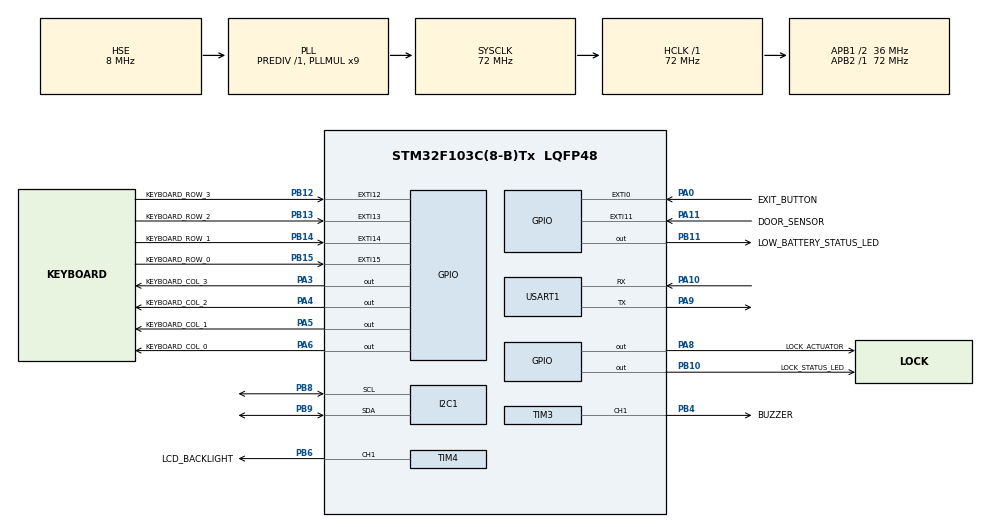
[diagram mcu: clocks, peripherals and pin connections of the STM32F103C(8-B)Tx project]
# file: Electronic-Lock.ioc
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Mcu.Family=STM32F1
Mcu.Name=STM32F103C(8-B)Tx
Mcu.Package=LQFP48
NVIC.EXTI0_IRQn=true\:0\:0\:false\:false\:true\:true\:true\:true
NVIC.EXTI15_10_IRQn=true\:0\:0\:false\:false\:true\:true\:true\:true
NVIC.PriorityGroup=NVIC_PRIORITYGROUP_4
NVIC.TIM1_UP_IRQn=true\:15\:0\:false\:false\:true\:false\:true\:true
NVIC.TimeBase=TIM1_UP_IRQn
NVIC.TimeBaseIP=TIM1
PA0-WKUP.GPIO_Label=EXIT_BUTTON
PA0-WKUP.GPIO_ModeDefaultEXTI=GPIO_MODE_IT_RISING_FALLING
PA0-WKUP.GPIO_PuPd=GPIO_PULLUP
PA0-WKUP.Signal=GPXTI0
PA10.Mode=Asynchronous
PA10.Signal=USART1_RX
PA11.GPIO_Label=DOOR_SENSOR
PA11.GPIO_ModeDefaultEXTI=GPIO_MODE_IT_RISING_FALLING
PA11.GPIO_PuPd=GPIO_PULLUP
PA11.Signal=GPXTI11
PA13.Mode=Serial_Wire
PA13.Signal=SYS_JTMS-SWDIO
PA14.Mode=Serial_Wire
PA14.Signal=SYS_JTCK-SWCLK
PA3.GPIO_Label=KEYBOARD_COL_3
PA3.GPIO_ModeDefaultOutputPP=GPIO_MODE_OUTPUT_PP
PA3.GPIO_PuPd=GPIO_NOPULL
PA3.GPIO_Speed=GPIO_SPEED_FREQ_HIGH
PA3.PinState=GPIO_PIN_RESET
PA3.Signal=GPIO_Output
PA4.GPIO_Label=KEYBOARD_COL_2
PA4.GPIO_ModeDefaultOutputPP=GPIO_MODE_OUTPUT_PP
PA4.GPIO_PuPd=GPIO_NOPULL
PA4.GPIO_Speed=GPIO_SPEED_FREQ_HIGH
PA4.PinState=GPIO_PIN_RESET
PA4.Signal=GPIO_Output
PA5.GPIO_Label=KEYBOARD_COL_1
PA5.GPIO_ModeDefaultOutputPP=GPIO_MODE_OUTPUT_PP
PA5.GPIO_PuPd=GPIO_NOPULL
PA5.GPIO_Speed=GPIO_SPEED_FREQ_HIGH
PA5.PinState=GPIO_PIN_RESET
PA5.Signal=GPIO_Output
PA6.GPIO_Label=KEYBOARD_COL_0
PA6.GPIO_ModeDefaultOutputPP=GPIO_MODE_OUTPUT_PP
PA6.GPIO_PuPd=GPIO_NOPULL
PA6.GPIO_Speed=GPIO_SPEED_FREQ_HIGH
PA6.PinState=GPIO_PIN_RESET
PA6.Signal=GPIO_Output
PA8.GPIO_Label=LOCK_ACTUATOR
PA8.GPIO_ModeDefaultOutputPP=GPIO_MODE_OUTPUT_PP
PA8.GPIO_PuPd=GPIO_NOPULL
PA8.GPIO_Speed=GPIO_SPEED_FREQ_HIGH
PA8.PinState=GPIO_PIN_RESET
PA8.Signal=GPIO_Output
PA9.Mode=Asynchronous
PA9.Signal=USART1_TX
PB10.GPIO_Label=LOCK_STATUS_LED
PB10.GPIO_ModeDefaultOutputPP=GPIO_MODE_OUTPUT_PP
PB10.GPIO_PuPd=GPIO_NOPULL
PB10.GPIO_Speed=GPIO_SPEED_FREQ_HIGH
PB10.PinState=GPIO_PIN_RESET
PB10.Signal=GPIO_Output
PB11.GPIO_Label=LOW_BATTERY_STATUS_LED
PB11.GPIO_ModeDefaultOutputPP=GPIO_MODE_OUTPUT_PP
PB11.GPIO_PuPd=GPIO_NOPULL
PB11.GPIO_Speed=GPIO_SPEED_FREQ_HIGH
PB11.PinState=GPIO_PIN_RESET
PB11.Signal=GPIO_Output
PB12.GPIO_Label=KEYBOARD_ROW_3
PB12.GPIO_ModeDefaultEXTI=GPIO_MODE_IT_RISING_FALLING
PB12.GPIO_PuPd=GPIO_PULLUP
PB12.Signal=GPXTI12
PB13.GPIO_Label=KEYBOARD_ROW_2
PB13.GPIO_ModeDefaultEXTI=GPIO_MODE_IT_RISING_FALLING
PB13.GPIO_PuPd=GPIO_PULLUP
PB13.Signal=GPXTI13
PB14.GPIO_Label=KEYBOARD_ROW_1
PB14.GPIO_ModeDefaultEXTI=GPIO_MODE_IT_RISING_FALLING
PB14.GPIO_PuPd=GPIO_PULLUP
PB14.Signal=GPXTI14
PB15.GPIO_Label=KEYBOARD_ROW_0
PB15.GPIO_ModeDefaultEXTI=GPIO_MODE_IT_RISING_FALLING
PB15.GPIO_PuPd=GPIO_PULLUP
PB15.Signal=GPXTI15
PB4.GPIO_Label=BUZZER
PB4.Signal=S_TIM3_CH1
PB6.GPIO_Label=LCD_BACKLIGHT
PB6.Signal=S_TIM4_CH1
PB8.Mode=I2C
PB8.Signal=I2C1_SCL
PB9.Mode=I2C
PB9.Signal=I2C1_SDA
PD0-OSC_IN.Mode=HSE-External-Oscillator
PD0-OSC_IN.Signal=RCC_OSC_IN
PD1-OSC_OUT.Mode=HSE-External-Oscillator
PD1-OSC_OUT.Signal=RCC_OSC_OUT
ProjectManager.HeapSize=0x200
ProjectManager.StackSize=0x400
ProjectManager.TargetToolchain=CMake
RCC.AHBFreq_Value=72000000
RCC.APB1CLKDivider=RCC_HCLK_DIV2
RCC.APB1Freq_Value=36000000
RCC.APB1TimFreq_Value=72000000
RCC.APB2Freq_Value=72000000
RCC.APB2TimFreq_Value=72000000
RCC.HCLKFreq_Value=72000000
RCC.PLLMUL=RCC_PLL_MUL9
RCC.PLLSourceVirtual=RCC_PLLSOURCE_HSE
RCC.SYSCLKFreq_VALUE=72000000
RCC.SYSCLKSource=RCC_SYSCLKSOURCE_PLLCLK
RCC.USBFreq_Value=72000000
SH.S_TIM3_CH1.0=TIM3_CH1,PWM Generation1 CH1
SH.S_TIM4_CH1.0=TIM4_CH1,PWM Generation1 CH1
TIM2.Prescaler=71
TIM3.Channel-PWM\ Generation1\ CH1=TIM_CHANNEL_1
TIM3.Prescaler=99
TIM4.Channel-PWM\ Generation1\ CH1=TIM_CHANNEL_1
TIM4.Prescaler=999
USART1.VirtualMode=VM_ASYNC
VP_SYS_VS_tim1.Mode=TIM1
VP_TIM2_VS_ClockSourceINT.Mode=Internal
VP_TIM3_VS_ClockSourceINT.Mode=Internal
VP_TIM4_VS_ClockSourceINT.Mode=Internal
board=custom

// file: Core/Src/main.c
/* USER CODE BEGIN Header */
/**
  ******************************************************************************
  * @file           : main.c
  * @brief          : Main program body
  ******************************************************************************
  * @attention
  *
  * Copyright (c) 2026 STMicroelectronics.
  * All rights reserved.
  *
  * This software is licensed under terms that can be found in the LICENSE file
  * in the root directory of this software component.
  * If no LICENSE file comes with this software, it is provided AS-IS.
  *
  ******************************************************************************
  */
/* USER CODE END Header */
#include "main.h"
#include "i2c.h"
#include "tim.h"
#include "usart.h"
#include "gpio.h"

/* USER CODE BEGIN Includes */
#include "App_Core.h"

/* USER CODE END Includes */

void SystemClock_Config(void);

int main(void)
{

  /* MCU Configuration--------------------------------------------------------*/

  /* Reset of all peripherals, Initializes the Flash interface and the Systick. */
  HAL_Init();

  /* Configure the system clock */
  SystemClock_Config();

  /* Initialize all configured peripherals */
  MX_GPIO_Init();
  MX_I2C1_Init();
  MX_TIM2_Init();
  MX_TIM3_Init();
  MX_TIM4_Init();
  MX_USART1_UART_Init();
  /* USER CODE BEGIN 2 */
  (void)App_Init();
  /* USER CODE END 2 */

  /* Infinite loop */
  while (1)
  {
    App_ReadInput();
    App_Dispatch();

  }
}

void SystemClock_Config(void)
{
  RCC_OscInitTypeDef RCC_OscInitStruct = {0};
  RCC_ClkInitTypeDef RCC_ClkInitStruct = {0};

  /** Initializes the RCC Oscillators according to the specified parameters
  * in the RCC_OscInitTypeDef structure.
  */
  RCC_OscInitStruct.OscillatorType = RCC_OSCILLATORTYPE_HSE;
  RCC_OscInitStruct.HSEState = RCC_HSE_ON;
  RCC_OscInitStruct.HSEPredivValue = RCC_HSE_PREDIV_DIV1;
  RCC_OscInitStruct.HSIState = RCC_HSI_ON;
  RCC_OscInitStruct.PLL.PLLState = RCC_PLL_ON;
  RCC_OscInitStruct.PLL.PLLSource = RCC_PLLSOURCE_HSE;
  RCC_OscInitStruct.PLL.PLLMUL = RCC_PLL_MUL9;
  if (HAL_RCC_OscConfig(&RCC_OscInitStruct) != HAL_OK)
  {
    Error_Handler();
  }

  /** Initializes the CPU, AHB and APB buses clocks
  */
  RCC_ClkInitStruct.ClockType = RCC_CLOCKTYPE_HCLK|RCC_CLOCKTYPE_SYSCLK
                              |RCC_CLOCKTYPE_PCLK1|RCC_CLOCKTYPE_PCLK2;
  RCC_ClkInitStruct.SYSCLKSource = RCC_SYSCLKSOURCE_PLLCLK;
  RCC_ClkInitStruct.AHBCLKDivider = RCC_SYSCLK_DIV1;
  RCC_ClkInitStruct.APB1CLKDivider = RCC_HCLK_DIV2;
  RCC_ClkInitStruct.APB2CLKDivider = RCC_HCLK_DIV1;

  if (HAL_RCC_ClockConfig(&RCC_ClkInitStruct, FLASH_LATENCY_2) != HAL_OK)
  {
    Error_Handler();
  }
}

void HAL_TIM_PeriodElapsedCallback(TIM_HandleTypeDef *htim)
{
  if (htim->Instance == TIM1)
  {
    HAL_IncTick();
  }
}

void Error_Handler(void)
{
  __disable_irq();
  while (1)
  {
  }
}
